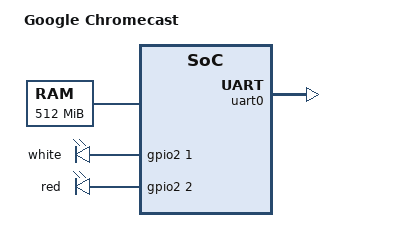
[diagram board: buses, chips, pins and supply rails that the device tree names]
/*
 * Device Tree file for Google Chromecast
 *
 * Sebastian Hesselbarth <sebastian.hesselbarth@gmail.com>
 *
 * This file is licensed under the terms of the GNU General Public
 * License version 2.  This program is licensed "as is" without any
 * warranty of any kind, whether express or implied.
 */

/dts-v1/;

#include "berlin2cd.dtsi"

/ {
	model = "Google Chromecast";
	compatible = "google,chromecast", "marvell,berlin2cd", "marvell,berlin";

	chosen {
		bootargs = "console=ttyS0,115200 earlyprintk";
	};

	memory {
		device_type = "memory";
		reg = <0x00000000 0x20000000>; /* 512 MB */
	};

	leds {
		compatible = "gpio-leds";

		white {
			label = "white";
			gpios = <&gpio2 1 0>;
			barebox,default-trigger = "panic";
		};

		red {
			label = "red";
			gpios = <&gpio2 2 0>;
			barebox,default-trigger = "heartbeat";
		};
	};
};

&uart0 { status = "okay"; };
